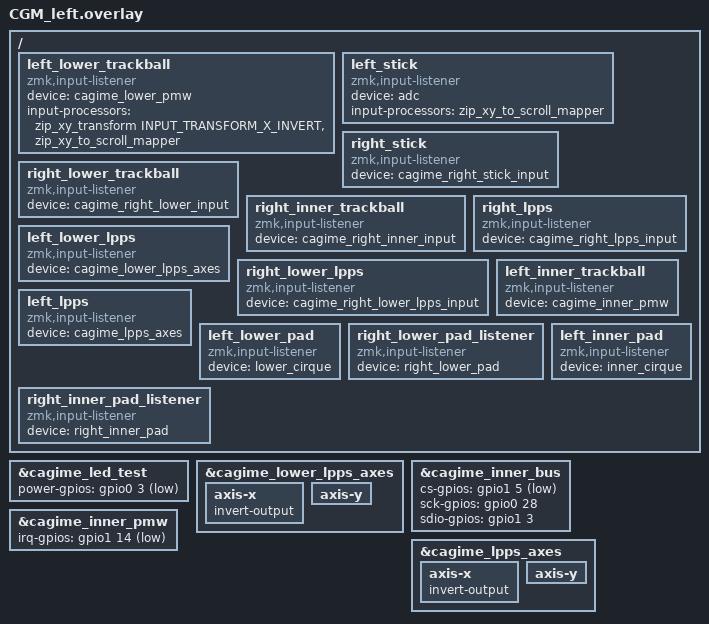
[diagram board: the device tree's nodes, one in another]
#include "CGM.dtsi"

&cagime_led_test {
    power-gpios = <&gpio0 3 GPIO_ACTIVE_LOW>; /* JLC U103 pad 2 / D1 */
};

/ {
    left_lower_trackball {
        compatible = "zmk,input-listener";
        device = <&cagime_lower_pmw>;
        input-processors = <&zip_xy_transform INPUT_TRANSFORM_X_INVERT>,
                           <&zip_xy_to_scroll_mapper>;
    };

    left_stick {
        compatible = "zmk,input-listener";
        device = <&adc>;
        input-processors = <&zip_xy_to_scroll_mapper>;
    };

    right_stick {
        compatible = "zmk,input-listener";
        device = <&cagime_right_stick_input>;
    };

    right_lower_trackball {
        compatible = "zmk,input-listener";
        device = <&cagime_right_lower_input>;
    };

    right_inner_trackball {
        compatible = "zmk,input-listener";
        device = <&cagime_right_inner_input>;
    };

    right_lpps {
        compatible = "zmk,input-listener";
        device = <&cagime_right_lpps_input>;
    };
};

&cagime_lower_lpps_axes {
    axis-x { invert-output; };
    axis-y { /delete-property/ invert-output; };
};
/ {
    left_lower_lpps { compatible = "zmk,input-listener"; device = <&cagime_lower_lpps_axes>; };
    right_lower_lpps { compatible = "zmk,input-listener"; device = <&cagime_right_lower_lpps_input>; };
};

/* Inner socket on the AAA R01 with corrected J5 routing. */
#include "cagime_inner_pmw3610.dtsi"

#define CAGIME_LPPS_PSELS <NRF_PSEL(SPIM_SCK, 1, 3)>, \
                         <NRF_PSEL(SPIM_MOSI, 1, 5)>, \
                         <NRF_PSEL(SPIM_MISO, 0, 28)>
#include "cagime_lpps.dtsi"

#define CAGIME_INNER_ENCODER_A <&gpio1 5 (GPIO_ACTIVE_HIGH | GPIO_PULL_UP)>
#define CAGIME_INNER_ENCODER_B <&gpio0 28 (GPIO_ACTIVE_HIGH | GPIO_PULL_UP)>
#define CAGIME_INNER_KEY_GPIO <&gpio1 5 (GPIO_ACTIVE_LOW | GPIO_PULL_UP)>
#include "cagime_inner_gpio.dtsi"

/* J5 pads 1 through 4: XIAO footprint pads 22, 3, 10 and 21. */
&cagime_inner_bus {
    cs-gpios = <&gpio1 5 GPIO_ACTIVE_LOW>;
    sck-gpios = <&gpio0 28 GPIO_ACTIVE_HIGH>;
    sdio-gpios = <&gpio1 3 GPIO_ACTIVE_HIGH>;
};

&cagime_inner_pmw {
    irq-gpios = <&gpio1 14 (GPIO_ACTIVE_LOW | GPIO_PULL_UP)>;
};

&cagime_lpps_axes {
    axis-x { invert-output; };
    axis-y { /delete-property/ invert-output; };
};

/ {
    left_inner_trackball {
        compatible = "zmk,input-listener";
        device = <&cagime_inner_pmw>;
    };

    left_lpps {
        compatible = "zmk,input-listener";
        device = <&cagime_lpps_axes>;
    };
};

#define PAT_BUS cagime_inner_pat_bus
#define PAT_NODE inner-pat-bus
#define PAT_SENSOR cagime_inner_pat
#define PAT_SCL <&gpio1 3 (GPIO_ACTIVE_HIGH | GPIO_OPEN_DRAIN)>
#define PAT_SDA <&gpio0 28 (GPIO_ACTIVE_HIGH | GPIO_OPEN_DRAIN)>
#define PAT_IRQ <&gpio1 14 (GPIO_ACTIVE_LOW | GPIO_PULL_UP)>
#include "cagime_pat_slot.dtsi"

#define CIRQUE_BUS inner_cirque_bus
#define CIRQUE_SOCKET inner_socket
#define CIRQUE_DEVICE inner_cirque
#define CIRQUE_SDA <&gpio1 3 (GPIO_ACTIVE_HIGH | GPIO_OPEN_DRAIN)>
#define CIRQUE_SCL <&gpio1 14 (GPIO_ACTIVE_HIGH | GPIO_OPEN_DRAIN)>
#define CIRQUE_DR <&gpio0 28 GPIO_ACTIVE_HIGH>
#include "cirque_slot.dtsi"
/ { left_lower_pad { compatible = "zmk,input-listener"; device = <&lower_cirque>; }; };
/ { right_lower_pad_listener { compatible = "zmk,input-listener"; device = <&right_lower_pad>; }; };
/ { left_inner_pad { compatible = "zmk,input-listener"; device = <&inner_cirque>; }; };
/ { right_inner_pad_listener { compatible = "zmk,input-listener"; device = <&right_inner_pad>; }; };
